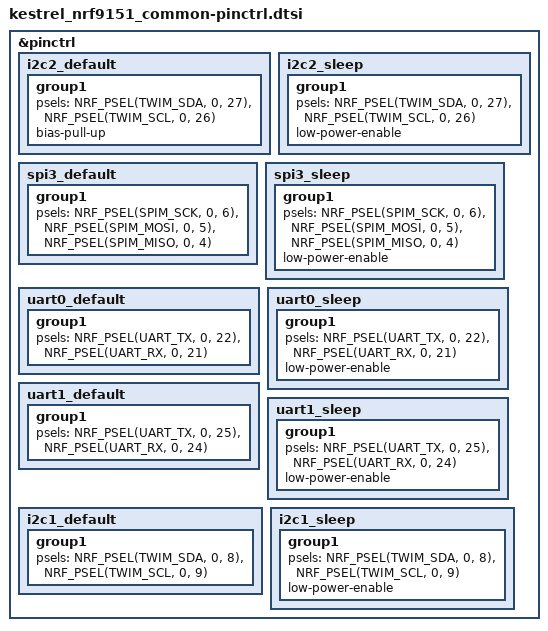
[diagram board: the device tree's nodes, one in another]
/*
 * Copyright (c) 2024 Nordic Semiconductor
 * SPDX-License-Identifier: LicenseRef-Nordic-5-Clause
 */

&pinctrl {
	/* PWM0 pinctrl removed - RGB LEDs not present on standalone design */

	i2c2_default: i2c2_default {
		group1 {
			psels = <NRF_PSEL(TWIM_SDA, 0, 27)>,
				<NRF_PSEL(TWIM_SCL, 0, 26)>;
				bias-pull-up;
		};
	};

	i2c2_sleep: i2c2_sleep {
		group1 {
			psels = <NRF_PSEL(TWIM_SDA, 0, 27)>,
				<NRF_PSEL(TWIM_SCL, 0, 26)>;
			low-power-enable;
		};
	};

	spi3_default: spi3_default {
		group1 {
			psels = <NRF_PSEL(SPIM_SCK, 0, 6)>,
				<NRF_PSEL(SPIM_MOSI, 0, 5)>,
				<NRF_PSEL(SPIM_MISO, 0, 4)>;
		};
	};

	spi3_sleep: spi3_sleep {
		group1 {
			psels = <NRF_PSEL(SPIM_SCK, 0, 6)>,
				<NRF_PSEL(SPIM_MOSI, 0, 5)>,
				<NRF_PSEL(SPIM_MISO, 0, 4)>;
			low-power-enable;
		};
	};

	uart0_default: uart0_default {
		group1 {
			psels = <NRF_PSEL(UART_TX, 0, 22)>,
				<NRF_PSEL(UART_RX, 0, 21)>;
		};
	};

	uart0_sleep: uart0_sleep {
		group1 {
			psels = <NRF_PSEL(UART_TX, 0, 22)>,
				<NRF_PSEL(UART_RX, 0, 21)>;
			low-power-enable;
		};
	};

	uart1_default: uart1_default {
		group1 {
			psels = <NRF_PSEL(UART_TX, 0, 25)>,
				<NRF_PSEL(UART_RX, 0, 24)>;
		};
	};

	uart1_sleep: uart1_sleep {
		group1 {
			psels = <NRF_PSEL(UART_TX, 0, 25)>,
				<NRF_PSEL(UART_RX, 0, 24)>;
			low-power-enable;
		};
	};


	i2c1_default: i2c1_default {
		group1 {
			psels = <NRF_PSEL(TWIM_SDA, 0, 8)>,
				<NRF_PSEL(TWIM_SCL, 0, 9)>;
		};
	};

	i2c1_sleep: i2c1_sleep {
		group1 {
			psels = <NRF_PSEL(TWIM_SDA, 0, 8)>,
				<NRF_PSEL(TWIM_SCL, 0, 9)>;
			low-power-enable;
		};
	};



};
